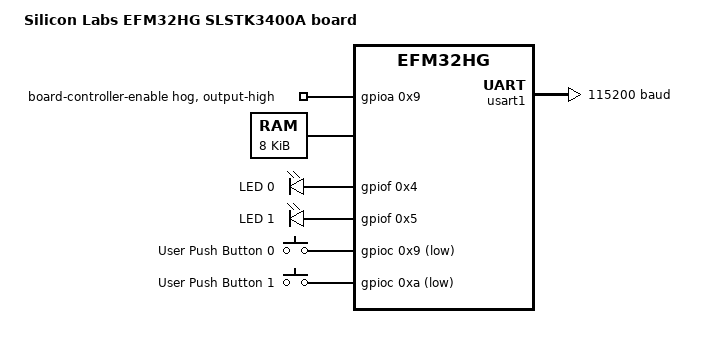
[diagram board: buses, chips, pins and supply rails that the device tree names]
/dts-v1/;

/* node '/' defined in zephyr/dts/common/skeleton.dtsi:9 */
/ {
	#address-cells = < 0x1 >;                        /* in zephyr/dts/common/skeleton.dtsi:10 */
	#size-cells = < 0x1 >;                           /* in zephyr/dts/common/skeleton.dtsi:11 */
	model = "Silicon Labs EFM32HG SLSTK3400A board"; /* in zephyr/boards/silabs/starter_kits/slstk3400a/slstk3400a.dts:13 */
	compatible = "silabs,slstk3400a",
	             "silabs,efm32hg";                   /* in zephyr/boards/silabs/starter_kits/slstk3400a/slstk3400a.dts:14 */

	/* node '/chosen' defined in zephyr/dts/common/skeleton.dtsi:13 */
	chosen {
		zephyr,flash-controller = &msc; /* in zephyr/dts/arm/silabs/efm32hg.dtsi:9 */
		zephyr,console = &usart1;       /* in zephyr/boards/silabs/starter_kits/slstk3400a/slstk3400a.dts:17 */
		zephyr,flash = &flash0;         /* in zephyr/boards/silabs/starter_kits/slstk3400a/slstk3400a.dts:18 */
		zephyr,shell-uart = &usart1;    /* in zephyr/boards/silabs/starter_kits/slstk3400a/slstk3400a.dts:19 */
		zephyr,sram = &sram0;           /* in zephyr/boards/silabs/starter_kits/slstk3400a/slstk3400a.dts:20 */
	};

	/* node '/aliases' defined in zephyr/dts/common/skeleton.dtsi:15 */
	aliases {
		led0 = &led0;   /* in zephyr/boards/silabs/starter_kits/slstk3400a/slstk3400a.dts:25 */
		led1 = &led1;   /* in zephyr/boards/silabs/starter_kits/slstk3400a/slstk3400a.dts:26 */
		sw0 = &button0; /* in zephyr/boards/silabs/starter_kits/slstk3400a/slstk3400a.dts:27 */
		sw1 = &button1; /* in zephyr/boards/silabs/starter_kits/slstk3400a/slstk3400a.dts:28 */
	};

	/* node '/soc' defined in zephyr/dts/arm/armv6-m.dtsi:6 */
	soc {
		#address-cells = < 0x1 >;            /* in zephyr/dts/arm/armv6-m.dtsi:7 */
		#size-cells = < 0x1 >;               /* in zephyr/dts/arm/armv6-m.dtsi:8 */
		interrupt-parent = < &nvic >;        /* in zephyr/dts/arm/armv6-m.dtsi:10 */
		ranges;                              /* in zephyr/dts/arm/armv6-m.dtsi:11 */
		compatible = "silabs,efm32hg322f64",
		             "silabs,efm32hg",
		             "silabs,efm32",
		             "simple-bus";           /* in zephyr/dts/arm/silabs/efm32hg322f64.dtsi:12 */

		/* node '/soc/interrupt-controller@e000e100' defined in zephyr/dts/arm/armv6-m.dtsi:13 */
		nvic: interrupt-controller@e000e100 {
			#address-cells = < 0x1 >;            /* in zephyr/dts/arm/armv6-m.dtsi:14 */
			compatible = "arm,v6m-nvic";         /* in zephyr/dts/arm/armv6-m.dtsi:15 */
			reg = < 0xe000e100 0xc00 >;          /* in zephyr/dts/arm/armv6-m.dtsi:16 */
			interrupt-controller;                /* in zephyr/dts/arm/armv6-m.dtsi:17 */
			#interrupt-cells = < 0x2 >;          /* in zephyr/dts/arm/armv6-m.dtsi:18 */
			arm,num-irq-priority-bits = < 0x2 >; /* in zephyr/dts/arm/silabs/efm32hg.dtsi:154 */
			phandle = < 0x1 >;                   /* in zephyr/dts/arm/armv6-m.dtsi:10 */
		};

		/* node '/soc/timer@e000e010' defined in zephyr/dts/arm/armv6-m.dtsi:21 */
		systick: timer@e000e010 {
			compatible = "arm,armv6m-systick"; /* in zephyr/dts/arm/armv6-m.dtsi:22 */
			reg = < 0xe000e010 0x10 >;         /* in zephyr/dts/arm/armv6-m.dtsi:23 */
		};

		/* node '/soc/flash-controller@400c0000' defined in zephyr/dts/arm/silabs/efm32hg.dtsi:27 */
		msc: flash-controller@400c0000 {
			compatible = "silabs,gecko-flash-controller"; /* in zephyr/dts/arm/silabs/efm32hg.dtsi:28 */
			reg = < 0x400c0000 0x5c >;                    /* in zephyr/dts/arm/silabs/efm32hg.dtsi:29 */
			interrupts = < 0xf 0x0 >;                     /* in zephyr/dts/arm/silabs/efm32hg.dtsi:30 */
			#address-cells = < 0x1 >;                     /* in zephyr/dts/arm/silabs/efm32hg.dtsi:32 */
			#size-cells = < 0x1 >;                        /* in zephyr/dts/arm/silabs/efm32hg.dtsi:33 */

			/* node '/soc/flash-controller@400c0000/flash@0' defined in zephyr/dts/arm/silabs/efm32hg.dtsi:35 */
			flash0: flash@0 {
				compatible = "soc-nv-flash";  /* in zephyr/dts/arm/silabs/efm32hg.dtsi:36 */
				write-block-size = < 0x4 >;   /* in zephyr/dts/arm/silabs/efm32hg.dtsi:37 */
				erase-block-size = < 0x400 >; /* in zephyr/dts/arm/silabs/efm32hg.dtsi:38 */
				reg = < 0x0 0x10000 >;        /* in zephyr/dts/arm/silabs/efm32hg322f64.dtsi:17 */

				/* node '/soc/flash-controller@400c0000/flash@0/partitions' defined in zephyr/boards/silabs/starter_kits/slstk3400a/slstk3400a.dts:94 */
				partitions {
					compatible = "fixed-partitions"; /* in zephyr/boards/silabs/starter_kits/slstk3400a/slstk3400a.dts:95 */
					#address-cells = < 0x1 >;        /* in zephyr/boards/silabs/starter_kits/slstk3400a/slstk3400a.dts:96 */
					#size-cells = < 0x1 >;           /* in zephyr/boards/silabs/starter_kits/slstk3400a/slstk3400a.dts:97 */

					/* node '/soc/flash-controller@400c0000/flash@0/partitions/partition@f000' defined in zephyr/boards/silabs/starter_kits/slstk3400a/slstk3400a.dts:100 */
					storage_partition: partition@f000 {
						reg = < 0xf000 0x1000 >; /* in zephyr/boards/silabs/starter_kits/slstk3400a/slstk3400a.dts:101 */
						label = "storage";       /* in zephyr/boards/silabs/starter_kits/slstk3400a/slstk3400a.dts:102 */
					};
				};
			};
		};

		/* node '/soc/usart@4000c000' defined in zephyr/dts/arm/silabs/efm32hg.dtsi:42 */
		usart0: usart@4000c000 {
			compatible = "silabs,gecko-usart"; /* in zephyr/dts/arm/silabs/efm32hg.dtsi:43 */
			reg = < 0x4000c000 0x400 >;        /* in zephyr/dts/arm/silabs/efm32hg.dtsi:44 */
			interrupts = < 0x11 0x0 >,
			             < 0x12 0x0 >;         /* in zephyr/dts/arm/silabs/efm32hg.dtsi:45 */
			interrupt-names = "rx",
			                  "tx";            /* in zephyr/dts/arm/silabs/efm32hg.dtsi:46 */
			peripheral-id = < 0x0 >;           /* in zephyr/dts/arm/silabs/efm32hg.dtsi:47 */
			status = "disabled";               /* in zephyr/dts/arm/silabs/efm32hg.dtsi:48 */
		};

		/* node '/soc/usart@4000c400' defined in zephyr/dts/arm/silabs/efm32hg.dtsi:51 */
		usart1: usart@4000c400 {
			compatible = "silabs,gecko-usart"; /* in zephyr/dts/arm/silabs/efm32hg.dtsi:52 */
			reg = < 0x4000c400 0x400 >;        /* in zephyr/dts/arm/silabs/efm32hg.dtsi:53 */
			interrupts = < 0x8 0x0 >,
			             < 0x9 0x0 >;          /* in zephyr/dts/arm/silabs/efm32hg.dtsi:54 */
			interrupt-names = "rx",
			                  "tx";            /* in zephyr/dts/arm/silabs/efm32hg.dtsi:55 */
			peripheral-id = < 0x1 >;           /* in zephyr/dts/arm/silabs/efm32hg.dtsi:56 */
			current-speed = < 0x1c200 >;       /* in zephyr/boards/silabs/starter_kits/slstk3400a/slstk3400a.dts:87 */
			location-rx = < 0x4 0x0 0x0 >;     /* in zephyr/boards/silabs/starter_kits/slstk3400a/slstk3400a.dts:88 */
			location-tx = < 0x4 0x5 0x2 >;     /* in zephyr/boards/silabs/starter_kits/slstk3400a/slstk3400a.dts:89 */
			status = "okay";                   /* in zephyr/boards/silabs/starter_kits/slstk3400a/slstk3400a.dts:90 */
		};

		/* node '/soc/leuart@40084000' defined in zephyr/dts/arm/silabs/efm32hg.dtsi:60 */
		leuart0: leuart@40084000 {
			compatible = "silabs,gecko-leuart"; /* in zephyr/dts/arm/silabs/efm32hg.dtsi:61 */
			reg = < 0x40084000 0x400 >;         /* in zephyr/dts/arm/silabs/efm32hg.dtsi:62 */
			interrupts = < 0xa 0x0 >;           /* in zephyr/dts/arm/silabs/efm32hg.dtsi:63 */
			peripheral-id = < 0x0 >;            /* in zephyr/dts/arm/silabs/efm32hg.dtsi:64 */
			status = "disabled";                /* in zephyr/dts/arm/silabs/efm32hg.dtsi:65 */
		};

		/* node '/soc/i2c@4000a000' defined in zephyr/dts/arm/silabs/efm32hg.dtsi:68 */
		i2c0: i2c@4000a000 {
			compatible = "silabs,gecko-i2c"; /* in zephyr/dts/arm/silabs/efm32hg.dtsi:69 */
			clock-frequency = < 0x186a0 >;   /* in zephyr/dts/arm/silabs/efm32hg.dtsi:70 */
			#address-cells = < 0x1 >;        /* in zephyr/dts/arm/silabs/efm32hg.dtsi:71 */
			#size-cells = < 0x0 >;           /* in zephyr/dts/arm/silabs/efm32hg.dtsi:72 */
			reg = < 0x4000a000 0x400 >;      /* in zephyr/dts/arm/silabs/efm32hg.dtsi:73 */
			interrupts = < 0x5 0x0 >;        /* in zephyr/dts/arm/silabs/efm32hg.dtsi:74 */
			status = "disabled";             /* in zephyr/dts/arm/silabs/efm32hg.dtsi:75 */
		};

		/* node '/soc/gpio@40006100' defined in zephyr/dts/arm/silabs/efm32hg.dtsi:78 */
		gpio@40006100 {
			compatible = "silabs,gecko-gpio"; /* in zephyr/dts/arm/silabs/efm32hg.dtsi:79 */
			reg = < 0x40006100 0xf00 >;       /* in zephyr/dts/arm/silabs/efm32hg.dtsi:80 */
			interrupts = < 0x1 0x0 0x6 0x0 >; /* in zephyr/dts/arm/silabs/efm32hg.dtsi:81 */
			interrupt-names = "GPIO_EVEN",
			                  "GPIO_ODD";     /* in zephyr/dts/arm/silabs/efm32hg.dtsi:82 */
			ranges;                           /* in zephyr/dts/arm/silabs/efm32hg.dtsi:84 */
			#address-cells = < 0x1 >;         /* in zephyr/dts/arm/silabs/efm32hg.dtsi:85 */
			#size-cells = < 0x1 >;            /* in zephyr/dts/arm/silabs/efm32hg.dtsi:86 */

			/* node '/soc/gpio@40006100/gpio@40006000' defined in zephyr/dts/arm/silabs/efm32hg.dtsi:88 */
			gpioa: gpio@40006000 {
				compatible = "silabs,gecko-gpio-port"; /* in zephyr/dts/arm/silabs/efm32hg.dtsi:89 */
				reg = < 0x40006000 0x24 >;             /* in zephyr/dts/arm/silabs/efm32hg.dtsi:90 */
				peripheral-id = < 0x0 >;               /* in zephyr/dts/arm/silabs/efm32hg.dtsi:91 */
				gpio-controller;                       /* in zephyr/dts/arm/silabs/efm32hg.dtsi:92 */
				#gpio-cells = < 0x2 >;                 /* in zephyr/dts/arm/silabs/efm32hg.dtsi:93 */
				status = "okay";                       /* in zephyr/boards/silabs/starter_kits/slstk3400a/slstk3400a.dts:69 */

				/* node '/soc/gpio@40006100/gpio@40006000/board-controller-enable' defined in zephyr/boards/silabs/starter_kits/slstk3400a/slstk3400a.dts:71 */
				board-controller-enable {
					gpio-hog;            /* in zephyr/boards/silabs/starter_kits/slstk3400a/slstk3400a.dts:72 */
					gpios = < 0x9 0x0 >; /* in zephyr/boards/silabs/starter_kits/slstk3400a/slstk3400a.dts:73 */
					output-high;         /* in zephyr/boards/silabs/starter_kits/slstk3400a/slstk3400a.dts:74 */
				};
			};

			/* node '/soc/gpio@40006100/gpio@40006024' defined in zephyr/dts/arm/silabs/efm32hg.dtsi:97 */
			gpiob: gpio@40006024 {
				compatible = "silabs,gecko-gpio-port"; /* in zephyr/dts/arm/silabs/efm32hg.dtsi:98 */
				reg = < 0x40006024 0x24 >;             /* in zephyr/dts/arm/silabs/efm32hg.dtsi:99 */
				peripheral-id = < 0x1 >;               /* in zephyr/dts/arm/silabs/efm32hg.dtsi:100 */
				gpio-controller;                       /* in zephyr/dts/arm/silabs/efm32hg.dtsi:101 */
				#gpio-cells = < 0x2 >;                 /* in zephyr/dts/arm/silabs/efm32hg.dtsi:102 */
				status = "disabled";                   /* in zephyr/dts/arm/silabs/efm32hg.dtsi:103 */
			};

			/* node '/soc/gpio@40006100/gpio@40006048' defined in zephyr/dts/arm/silabs/efm32hg.dtsi:106 */
			gpioc: gpio@40006048 {
				compatible = "silabs,gecko-gpio-port"; /* in zephyr/dts/arm/silabs/efm32hg.dtsi:107 */
				reg = < 0x40006048 0x24 >;             /* in zephyr/dts/arm/silabs/efm32hg.dtsi:108 */
				peripheral-id = < 0x2 >;               /* in zephyr/dts/arm/silabs/efm32hg.dtsi:109 */
				gpio-controller;                       /* in zephyr/dts/arm/silabs/efm32hg.dtsi:110 */
				#gpio-cells = < 0x2 >;                 /* in zephyr/dts/arm/silabs/efm32hg.dtsi:111 */
				status = "okay";                       /* in zephyr/boards/silabs/starter_kits/slstk3400a/slstk3400a.dts:79 */
				phandle = < 0x3 >;                     /* in zephyr/boards/silabs/starter_kits/slstk3400a/slstk3400a.dts:50 */
			};

			/* node '/soc/gpio@40006100/gpio@4000606c' defined in zephyr/dts/arm/silabs/efm32hg.dtsi:115 */
			gpiod: gpio@4000606c {
				compatible = "silabs,gecko-gpio-port"; /* in zephyr/dts/arm/silabs/efm32hg.dtsi:116 */
				reg = < 0x4000606c 0x24 >;             /* in zephyr/dts/arm/silabs/efm32hg.dtsi:117 */
				peripheral-id = < 0x3 >;               /* in zephyr/dts/arm/silabs/efm32hg.dtsi:118 */
				gpio-controller;                       /* in zephyr/dts/arm/silabs/efm32hg.dtsi:119 */
				#gpio-cells = < 0x2 >;                 /* in zephyr/dts/arm/silabs/efm32hg.dtsi:120 */
				status = "disabled";                   /* in zephyr/dts/arm/silabs/efm32hg.dtsi:121 */
			};

			/* node '/soc/gpio@40006100/gpio@40006090' defined in zephyr/dts/arm/silabs/efm32hg.dtsi:124 */
			gpioe: gpio@40006090 {
				compatible = "silabs,gecko-gpio-port"; /* in zephyr/dts/arm/silabs/efm32hg.dtsi:125 */
				reg = < 0x40006090 0x24 >;             /* in zephyr/dts/arm/silabs/efm32hg.dtsi:126 */
				peripheral-id = < 0x4 >;               /* in zephyr/dts/arm/silabs/efm32hg.dtsi:127 */
				gpio-controller;                       /* in zephyr/dts/arm/silabs/efm32hg.dtsi:128 */
				#gpio-cells = < 0x2 >;                 /* in zephyr/dts/arm/silabs/efm32hg.dtsi:129 */
				status = "disabled";                   /* in zephyr/dts/arm/silabs/efm32hg.dtsi:130 */
			};

			/* node '/soc/gpio@40006100/gpio@400060b4' defined in zephyr/dts/arm/silabs/efm32hg.dtsi:133 */
			gpiof: gpio@400060b4 {
				compatible = "silabs,gecko-gpio-port"; /* in zephyr/dts/arm/silabs/efm32hg.dtsi:134 */
				reg = < 0x400060b4 0x24 >;             /* in zephyr/dts/arm/silabs/efm32hg.dtsi:135 */
				peripheral-id = < 0x5 >;               /* in zephyr/dts/arm/silabs/efm32hg.dtsi:136 */
				gpio-controller;                       /* in zephyr/dts/arm/silabs/efm32hg.dtsi:137 */
				#gpio-cells = < 0x2 >;                 /* in zephyr/dts/arm/silabs/efm32hg.dtsi:138 */
				status = "okay";                       /* in zephyr/boards/silabs/starter_kits/slstk3400a/slstk3400a.dts:83 */
				phandle = < 0x2 >;                     /* in zephyr/boards/silabs/starter_kits/slstk3400a/slstk3400a.dts:35 */
			};
		};

		/* node '/soc/pin-controller' defined in zephyr/dts/arm/silabs/efm32hg.dtsi:143 */
		pinctrl: pin-controller {
			compatible = "silabs,gecko-pinctrl"; /* in zephyr/dts/arm/silabs/efm32hg.dtsi:148 */
		};
	};

	/* node '/cpus' defined in zephyr/dts/arm/silabs/efm32hg.dtsi:12 */
	cpus {
		#address-cells = < 0x1 >; /* in zephyr/dts/arm/silabs/efm32hg.dtsi:13 */
		#size-cells = < 0x0 >;    /* in zephyr/dts/arm/silabs/efm32hg.dtsi:14 */

		/* node '/cpus/cpu@0' defined in zephyr/dts/arm/silabs/efm32hg.dtsi:16 */
		cpu0: cpu@0 {
			compatible = "arm,cortex-m0+";   /* in zephyr/dts/arm/silabs/efm32hg.dtsi:17 */
			reg = < 0x0 >;                   /* in zephyr/dts/arm/silabs/efm32hg.dtsi:18 */
			clock-frequency = < 0x16e3600 >; /* in zephyr/boards/silabs/starter_kits/slstk3400a/slstk3400a.dts:65 */
		};
	};

	/* node '/memory@20000000' defined in zephyr/dts/arm/silabs/efm32hg.dtsi:22 */
	sram0: memory@20000000 {
		compatible = "mmio-sram";    /* in zephyr/dts/arm/silabs/efm32hg.dtsi:23 */
		reg = < 0x20000000 0x2000 >; /* in zephyr/dts/arm/silabs/efm32hg322f64.dtsi:21 */
	};

	/* node '/leds' defined in zephyr/boards/silabs/starter_kits/slstk3400a/slstk3400a.dts:31 */
	leds {
		compatible = "gpio-leds"; /* in zephyr/boards/silabs/starter_kits/slstk3400a/slstk3400a.dts:32 */

		/* node '/leds/led_0' defined in zephyr/boards/silabs/starter_kits/slstk3400a/slstk3400a.dts:34 */
		led0: led_0 {
			gpios = < &gpiof 0x4 0x0 >; /* in zephyr/boards/silabs/starter_kits/slstk3400a/slstk3400a.dts:35 */
			label = "LED 0";            /* in zephyr/boards/silabs/starter_kits/slstk3400a/slstk3400a.dts:36 */
		};

		/* node '/leds/led_1' defined in zephyr/boards/silabs/starter_kits/slstk3400a/slstk3400a.dts:39 */
		led1: led_1 {
			gpios = < &gpiof 0x5 0x0 >; /* in zephyr/boards/silabs/starter_kits/slstk3400a/slstk3400a.dts:40 */
			label = "LED 1";            /* in zephyr/boards/silabs/starter_kits/slstk3400a/slstk3400a.dts:41 */
		};
	};

	/* node '/buttons' defined in zephyr/boards/silabs/starter_kits/slstk3400a/slstk3400a.dts:45 */
	buttons {
		compatible = "gpio-keys"; /* in zephyr/boards/silabs/starter_kits/slstk3400a/slstk3400a.dts:46 */

		/* node '/buttons/button_0' defined in zephyr/boards/silabs/starter_kits/slstk3400a/slstk3400a.dts:48 */
		button0: button_0 {
			gpios = < &gpioc 0x9 0x1 >;   /* in zephyr/boards/silabs/starter_kits/slstk3400a/slstk3400a.dts:50 */
			label = "User Push Button 0"; /* in zephyr/boards/silabs/starter_kits/slstk3400a/slstk3400a.dts:51 */
			zephyr,code = < 0xb >;        /* in zephyr/boards/silabs/starter_kits/slstk3400a/slstk3400a.dts:52 */
		};

		/* node '/buttons/button_1' defined in zephyr/boards/silabs/starter_kits/slstk3400a/slstk3400a.dts:55 */
		button1: button_1 {
			gpios = < &gpioc 0xa 0x1 >;   /* in zephyr/boards/silabs/starter_kits/slstk3400a/slstk3400a.dts:57 */
			label = "User Push Button 1"; /* in zephyr/boards/silabs/starter_kits/slstk3400a/slstk3400a.dts:58 */
			zephyr,code = < 0x2 >;        /* in zephyr/boards/silabs/starter_kits/slstk3400a/slstk3400a.dts:59 */
		};
	};
};
